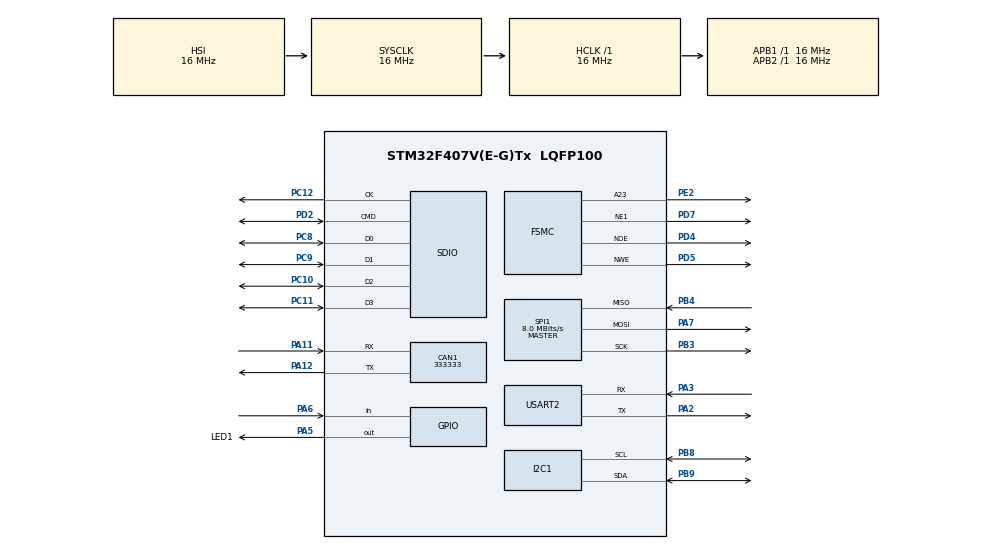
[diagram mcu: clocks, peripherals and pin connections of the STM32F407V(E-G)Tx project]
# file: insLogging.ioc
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CAN1.CalculateBaudRate=333333
CAN1.CalculateTimeBit=3000
CAN1.CalculateTimeQuantum=1000.0
Dma.I2C1_RX.0.Direction=DMA_PERIPH_TO_MEMORY
Dma.I2C1_RX.0.FIFOMode=DMA_FIFOMODE_DISABLE
Dma.I2C1_RX.0.Instance=DMA1_Stream0
Dma.I2C1_RX.0.MemDataAlignment=DMA_MDATAALIGN_BYTE
Dma.I2C1_RX.0.MemInc=DMA_MINC_ENABLE
Dma.I2C1_RX.0.Mode=DMA_NORMAL
Dma.I2C1_RX.0.PeriphDataAlignment=DMA_PDATAALIGN_BYTE
Dma.I2C1_RX.0.PeriphInc=DMA_PINC_DISABLE
Dma.I2C1_RX.0.Priority=DMA_PRIORITY_LOW
Dma.I2C1_TX.1.Direction=DMA_MEMORY_TO_PERIPH
Dma.I2C1_TX.1.FIFOMode=DMA_FIFOMODE_DISABLE
Dma.I2C1_TX.1.Instance=DMA1_Stream6
Dma.I2C1_TX.1.MemDataAlignment=DMA_MDATAALIGN_BYTE
Dma.I2C1_TX.1.MemInc=DMA_MINC_ENABLE
Dma.I2C1_TX.1.Mode=DMA_NORMAL
Dma.I2C1_TX.1.PeriphDataAlignment=DMA_PDATAALIGN_BYTE
Dma.I2C1_TX.1.PeriphInc=DMA_PINC_DISABLE
Dma.I2C1_TX.1.Priority=DMA_PRIORITY_LOW
Dma.Request0=I2C1_RX
Dma.Request1=I2C1_TX
Mcu.Family=STM32F4
Mcu.Name=STM32F407V(E-G)Tx
Mcu.Package=LQFP100
NVIC.DMA1_Stream0_IRQn=true\:0\:0\:false\:false\:true\:false\:true\:true
NVIC.DMA1_Stream6_IRQn=true\:0\:0\:false\:false\:true\:false\:true\:true
NVIC.PriorityGroup=NVIC_PRIORITYGROUP_4
PA11.Mode=CAN_Activate
PA11.Signal=CAN1_RX
PA12.Mode=CAN_Activate
PA12.Signal=CAN1_TX
PA13.Mode=Serial_Wire
PA13.Signal=SYS_JTMS-SWDIO
PA14.Mode=Serial_Wire
PA14.Signal=SYS_JTCK-SWCLK
PA2.Mode=Asynchronous
PA2.Signal=USART2_TX
PA3.Mode=Asynchronous
PA3.Signal=USART2_RX
PA5.GPIO_Label=LED1
PA5.Signal=GPIO_Output
PA6.Signal=GPIO_Input
PA7.Mode=Full_Duplex_Master
PA7.Signal=SPI1_MOSI
PB3.Mode=Full_Duplex_Master
PB3.Signal=SPI1_SCK
PB4.Mode=Full_Duplex_Master
PB4.Signal=SPI1_MISO
PB8.Mode=I2C
PB8.Signal=I2C1_SCL
PB9.Mode=I2C
PB9.Signal=I2C1_SDA
PC10.Mode=SD_4_bits_Wide_bus
PC10.Signal=SDIO_D2
PC11.Mode=SD_4_bits_Wide_bus
PC11.Signal=SDIO_D3
PC12.Mode=SD_4_bits_Wide_bus
PC12.Signal=SDIO_CK
PC8.Mode=SD_4_bits_Wide_bus
PC8.Signal=SDIO_D0
PC9.Mode=SD_4_bits_Wide_bus
PC9.Signal=SDIO_D1
PD2.Mode=SD_4_bits_Wide_bus
PD2.Signal=SDIO_CMD
PD4.Mode=Lcd1
PD4.Signal=FSMC_NOE
PD5.Mode=Lcd1
PD5.Signal=FSMC_NWE
PD7.Mode=NorPsramChipSelect1_1
PD7.Signal=FSMC_NE1
PE2.Mode=A23_1
PE2.Signal=FSMC_A23
ProjectManager.HeapSize=0x200
ProjectManager.StackSize=0x400
ProjectManager.TargetToolchain=STM32CubeIDE
RCC.48MHZClocksFreq_Value=48000000
RCC.AHBFreq_Value=16000000
RCC.APB1Freq_Value=16000000
RCC.APB1TimCLKDivider=1
RCC.APB1TimFreq_Value=16000000
RCC.APB2Freq_Value=16000000
RCC.APB2TimCLKDivider=1
RCC.APB2TimFreq_Value=16000000
RCC.CortexFreq_Value=16000000
RCC.HCLKFreq_Value=16000000
RCC.HSE_VALUE=25000000
RCC.HSI_VALUE=16000000
RCC.LSE_VALUE=32768
RCC.SYSCLKFreq_VALUE=16000000
RCC.VCOOutputFreq_Value=192000000
SPI1.CalculateBaudRate=8.0 MBits/s
SPI1.Direction=SPI_DIRECTION_2LINES
SPI1.Mode=SPI_MODE_MASTER
SPI1.VirtualType=VM_MASTER
USART2.VirtualMode=VM_ASYNC
VP_FATFS_VS_SDIO.Mode=SDIO
board=custom

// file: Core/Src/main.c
/* USER CODE BEGIN Header */
/**
  ******************************************************************************
  * @file           : main.c
  * @brief          : Main program body
  ******************************************************************************
  * @attention
  *
  * Copyright (c) 2025 STMicroelectronics.
  * All rights reserved.
  *
  * This software is licensed under terms that can be found in the LICENSE file
  * in the root directory of this software component.
  * If no LICENSE file comes with this software, it is provided AS-IS.
  *
  ******************************************************************************
  */
/* USER CODE END Header */
#include "main.h"
#include "fatfs.h"

/* USER CODE BEGIN Includes */
///////////////////////
/* USER CODE END Includes */

CAN_HandleTypeDef hcan1;

I2C_HandleTypeDef hi2c1;
DMA_HandleTypeDef hdma_i2c1_rx;
DMA_HandleTypeDef hdma_i2c1_tx;

SD_HandleTypeDef hsd;

SPI_HandleTypeDef hspi1;

UART_HandleTypeDef huart2;

SRAM_HandleTypeDef hsram1;

void SystemClock_Config(void);
static void MX_GPIO_Init(void);
static void MX_DMA_Init(void);
static void MX_I2C1_Init(void);
static void MX_USART2_UART_Init(void);
static void MX_SDIO_SD_Init(void);
static void MX_CAN1_Init(void);
static void MX_SPI1_Init(void);
static void MX_FSMC_Init(void);

int main(void)
{

  /* MCU Configuration--------------------------------------------------------*/

  /* Reset of all peripherals, Initializes the Flash interface and the Systick. */
  HAL_Init();

  /* Configure the system clock */
  SystemClock_Config();

  /* Initialize all configured peripherals */
  MX_GPIO_Init();
  MX_DMA_Init();
  MX_I2C1_Init();
  MX_USART2_UART_Init();
  MX_SDIO_SD_Init();
  MX_FATFS_Init();
  MX_CAN1_Init();
  MX_SPI1_Init();
  MX_FSMC_Init();
  /* USER CODE BEGIN 2 */
HAL_GPIO_WritePin(GPIOA, GPIO_PIN_6, GPIO_PIN_SET);
  /* USER CODE END 2 */

  /* Infinite loop */
  while (1)
  {

  }
}

void SystemClock_Config(void)
{
  RCC_OscInitTypeDef RCC_OscInitStruct = {0};
  RCC_ClkInitTypeDef RCC_ClkInitStruct = {0};

  /** Configure the main internal regulator output voltage
  */
  __HAL_RCC_PWR_CLK_ENABLE();
  __HAL_PWR_VOLTAGESCALING_CONFIG(PWR_REGULATOR_VOLTAGE_SCALE1);

  /** Initializes the RCC Oscillators according to the specified parameters
  * in the RCC_OscInitTypeDef structure.
  */
  RCC_OscInitStruct.OscillatorType = RCC_OSCILLATORTYPE_HSI;
  RCC_OscInitStruct.HSIState = RCC_HSI_ON;
  RCC_OscInitStruct.HSICalibrationValue = RCC_HSICALIBRATION_DEFAULT;
  RCC_OscInitStruct.PLL.PLLState = RCC_PLL_ON;
  RCC_OscInitStruct.PLL.PLLSource = RCC_PLLSOURCE_HSI;
  RCC_OscInitStruct.PLL.PLLM = 16;
  RCC_OscInitStruct.PLL.PLLN = 192;
  RCC_OscInitStruct.PLL.PLLP = RCC_PLLP_DIV2;
  RCC_OscInitStruct.PLL.PLLQ = 4;
  if (HAL_RCC_OscConfig(&RCC_OscInitStruct) != HAL_OK)
  {
    Error_Handler();
  }

  /** Initializes the CPU, AHB and APB buses clocks
  */
  RCC_ClkInitStruct.ClockType = RCC_CLOCKTYPE_HCLK|RCC_CLOCKTYPE_SYSCLK
                              |RCC_CLOCKTYPE_PCLK1|RCC_CLOCKTYPE_PCLK2;
  RCC_ClkInitStruct.SYSCLKSource = RCC_SYSCLKSOURCE_HSI;
  RCC_ClkInitStruct.AHBCLKDivider = RCC_SYSCLK_DIV1;
  RCC_ClkInitStruct.APB1CLKDivider = RCC_HCLK_DIV1;
  RCC_ClkInitStruct.APB2CLKDivider = RCC_HCLK_DIV1;

  if (HAL_RCC_ClockConfig(&RCC_ClkInitStruct, FLASH_LATENCY_0) != HAL_OK)
  {
    Error_Handler();
  }
}

static void MX_CAN1_Init(void)
{

  hcan1.Instance = CAN1;
  hcan1.Init.Prescaler = 16;
  hcan1.Init.Mode = CAN_MODE_NORMAL;
  hcan1.Init.SyncJumpWidth = CAN_SJW_1TQ;
  hcan1.Init.TimeSeg1 = CAN_BS1_1TQ;
  hcan1.Init.TimeSeg2 = CAN_BS2_1TQ;
  hcan1.Init.TimeTriggeredMode = DISABLE;
  hcan1.Init.AutoBusOff = DISABLE;
  hcan1.Init.AutoWakeUp = DISABLE;
  hcan1.Init.AutoRetransmission = DISABLE;
  hcan1.Init.ReceiveFifoLocked = DISABLE;
  hcan1.Init.TransmitFifoPriority = DISABLE;
  if (HAL_CAN_Init(&hcan1) != HAL_OK)
  {
    Error_Handler();
  }

}

static void MX_I2C1_Init(void)
{

  hi2c1.Instance = I2C1;
  hi2c1.Init.ClockSpeed = 100000;
  hi2c1.Init.DutyCycle = I2C_DUTYCYCLE_2;
  hi2c1.Init.OwnAddress1 = 0;
  hi2c1.Init.AddressingMode = I2C_ADDRESSINGMODE_7BIT;
  hi2c1.Init.DualAddressMode = I2C_DUALADDRESS_DISABLE;
  hi2c1.Init.OwnAddress2 = 0;
  hi2c1.Init.GeneralCallMode = I2C_GENERALCALL_DISABLE;
  hi2c1.Init.NoStretchMode = I2C_NOSTRETCH_DISABLE;
  if (HAL_I2C_Init(&hi2c1) != HAL_OK)
  {
    Error_Handler();
  }

}

static void MX_SDIO_SD_Init(void)
{

  hsd.Instance = SDIO;
  hsd.Init.ClockEdge = SDIO_CLOCK_EDGE_RISING;
  hsd.Init.ClockBypass = SDIO_CLOCK_BYPASS_DISABLE;
  hsd.Init.ClockPowerSave = SDIO_CLOCK_POWER_SAVE_DISABLE;
  hsd.Init.BusWide = SDIO_BUS_WIDE_1B;
  hsd.Init.HardwareFlowControl = SDIO_HARDWARE_FLOW_CONTROL_DISABLE;
  hsd.Init.ClockDiv = 0;
  /* USER CODE BEGIN SDIO_Init 2 */
  hsd.Init.BusWide = SDIO_BUS_WIDE_1B;

  if (HAL_SD_Init(&hsd) != HAL_OK)
  {
    Error_Handler();
  }
  if (HAL_SD_ConfigWideBusOperation(&hsd, SDIO_BUS_WIDE_4B) != HAL_OK)
  {
    Error_Handler();
  }
  /* USER CODE END SDIO_Init 2 */

}

static void MX_SPI1_Init(void)
{

  /* SPI1 parameter configuration*/
  hspi1.Instance = SPI1;
  hspi1.Init.Mode = SPI_MODE_MASTER;
  hspi1.Init.Direction = SPI_DIRECTION_2LINES;
  hspi1.Init.DataSize = SPI_DATASIZE_8BIT;
  hspi1.Init.CLKPolarity = SPI_POLARITY_LOW;
  hspi1.Init.CLKPhase = SPI_PHASE_1EDGE;
  hspi1.Init.NSS = SPI_NSS_SOFT;
  hspi1.Init.BaudRatePrescaler = SPI_BAUDRATEPRESCALER_2;
  hspi1.Init.FirstBit = SPI_FIRSTBIT_MSB;
  hspi1.Init.TIMode = SPI_TIMODE_DISABLE;
  hspi1.Init.CRCCalculation = SPI_CRCCALCULATION_DISABLE;
  hspi1.Init.CRCPolynomial = 10;
  if (HAL_SPI_Init(&hspi1) != HAL_OK)
  {
    Error_Handler();
  }

}

static void MX_USART2_UART_Init(void)
{

  huart2.Instance = USART2;
  huart2.Init.BaudRate = 115200;
  huart2.Init.WordLength = UART_WORDLENGTH_8B;
  huart2.Init.StopBits = UART_STOPBITS_1;
  huart2.Init.Parity = UART_PARITY_NONE;
  huart2.Init.Mode = UART_MODE_TX_RX;
  huart2.Init.HwFlowCtl = UART_HWCONTROL_NONE;
  huart2.Init.OverSampling = UART_OVERSAMPLING_16;
  if (HAL_UART_Init(&huart2) != HAL_OK)
  {
    Error_Handler();
  }

}

static void MX_DMA_Init(void)
{

  /* DMA controller clock enable */
  __HAL_RCC_DMA1_CLK_ENABLE();

  /* DMA interrupt init */
  /* DMA1_Stream0_IRQn interrupt configuration */
  HAL_NVIC_SetPriority(DMA1_Stream0_IRQn, 0, 0);
  HAL_NVIC_EnableIRQ(DMA1_Stream0_IRQn);
  /* DMA1_Stream6_IRQn interrupt configuration */
  HAL_NVIC_SetPriority(DMA1_Stream6_IRQn, 0, 0);
  HAL_NVIC_EnableIRQ(DMA1_Stream6_IRQn);

}

static void MX_GPIO_Init(void)
{
  GPIO_InitTypeDef GPIO_InitStruct = {0};

  /* GPIO Ports Clock Enable */
  __HAL_RCC_GPIOE_CLK_ENABLE();
  __HAL_RCC_GPIOA_CLK_ENABLE();
  __HAL_RCC_GPIOC_CLK_ENABLE();
  __HAL_RCC_GPIOD_CLK_ENABLE();
  __HAL_RCC_GPIOB_CLK_ENABLE();

  /*Configure GPIO pin Output Level */
  HAL_GPIO_WritePin(LED1_GPIO_Port, LED1_Pin, GPIO_PIN_RESET);

  /*Configure GPIO pin : LED1_Pin */
  GPIO_InitStruct.Pin = LED1_Pin;
  GPIO_InitStruct.Mode = GPIO_MODE_OUTPUT_PP;
  GPIO_InitStruct.Pull = GPIO_NOPULL;
  GPIO_InitStruct.Speed = GPIO_SPEED_FREQ_LOW;
  HAL_GPIO_Init(LED1_GPIO_Port, &GPIO_InitStruct);

  /*Configure GPIO pin : PA6 */
  GPIO_InitStruct.Pin = GPIO_PIN_6;
  GPIO_InitStruct.Mode = GPIO_MODE_INPUT;
  GPIO_InitStruct.Pull = GPIO_NOPULL;
  HAL_GPIO_Init(GPIOA, &GPIO_InitStruct);

}

/* FSMC initialization function */
static void MX_FSMC_Init(void)
{

  FSMC_NORSRAM_TimingTypeDef Timing = {0};

  /** Perform the SRAM1 memory initialization sequence
  */
  hsram1.Instance = FSMC_NORSRAM_DEVICE;
  hsram1.Extended = FSMC_NORSRAM_EXTENDED_DEVICE;
  /* hsram1.Init */
  hsram1.Init.NSBank = FSMC_NORSRAM_BANK1;
  hsram1.Init.DataAddressMux = FSMC_DATA_ADDRESS_MUX_DISABLE;
  hsram1.Init.MemoryType = FSMC_MEMORY_TYPE_SRAM;
  hsram1.Init.MemoryDataWidth = FSMC_NORSRAM_MEM_BUS_WIDTH_16;
  hsram1.Init.BurstAccessMode = FSMC_BURST_ACCESS_MODE_DISABLE;
  hsram1.Init.WaitSignalPolarity = FSMC_WAIT_SIGNAL_POLARITY_LOW;
  hsram1.Init.WrapMode = FSMC_WRAP_MODE_DISABLE;
  hsram1.Init.WaitSignalActive = FSMC_WAIT_TIMING_BEFORE_WS;
  hsram1.Init.WriteOperation = FSMC_WRITE_OPERATION_ENABLE;
  hsram1.Init.WaitSignal = FSMC_WAIT_SIGNAL_DISABLE;
  hsram1.Init.ExtendedMode = FSMC_EXTENDED_MODE_DISABLE;
  hsram1.Init.AsynchronousWait = FSMC_ASYNCHRONOUS_WAIT_DISABLE;
  hsram1.Init.WriteBurst = FSMC_WRITE_BURST_DISABLE;
  hsram1.Init.PageSize = FSMC_PAGE_SIZE_NONE;
  /* Timing */
  Timing.AddressSetupTime = 15;
  Timing.AddressHoldTime = 15;
  Timing.DataSetupTime = 255;
  Timing.BusTurnAroundDuration = 15;
  Timing.CLKDivision = 16;
  Timing.DataLatency = 17;
  Timing.AccessMode = FSMC_ACCESS_MODE_A;
  /* ExtTiming */

  if (HAL_SRAM_Init(&hsram1, &Timing, NULL) != HAL_OK)
  {
    Error_Handler( );
  }

}

void Error_Handler(void)
{
  __disable_irq();
  while (1)
  {
  }
}
